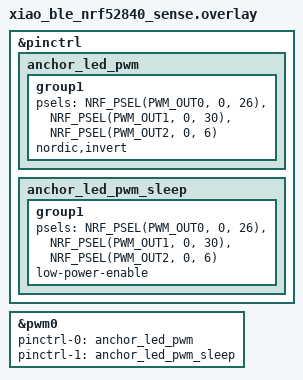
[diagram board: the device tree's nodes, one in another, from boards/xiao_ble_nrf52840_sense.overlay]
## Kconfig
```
mainmenu "ANCHOR native Nordic firmware"

source "Kconfig.zephyr"

config ANCHOR_LEGACY_BLE_DFU
	bool "Advertise legacy Bluetooth DFU for bench testing"
	help
	  Allow EdgeTX to enter the installed Adafruit S140 bootloader.
	  Enable only for controlled testing with the unsigned bench bootloader.
```

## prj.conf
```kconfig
#
# Copyright (c) 2025 Nordic Semiconductor
#
# SPDX-License-Identifier: LicenseRef-Nordic-5-Clause
#
CONFIG_NCS_SAMPLES_DEFAULTS=y

CONFIG_CONSOLE=y
CONFIG_CONSOLE_SUBSYS=y
CONFIG_CONSOLE_HANDLER=y
CONFIG_CONSOLE_GETCHAR=y

CONFIG_BT_DEVICE_NAME="Nordic_SCI"
CONFIG_BT=y
CONFIG_BT_SMP=y
CONFIG_BT_PERIPHERAL=y
CONFIG_BT_CENTRAL=y
CONFIG_BT_MAX_CONN=2
CONFIG_BT_BONDABLE=n

# Shorter Connection Intervals dependencies
CONFIG_BT_LE_EXTENDED_FEAT_SET=y
CONFIG_BT_SUBRATING=y

CONFIG_BT_FRAME_SPACE_UPDATE=y
CONFIG_BT_SHORTER_CONNECTION_INTERVALS=y

# Ensure the default event length is shorter than the minimum interval
CONFIG_BT_CTLR_SDC_MAX_CONN_EVENT_LEN_DEFAULT=750

CONFIG_BT_SCAN=y
CONFIG_BT_SCAN_FILTER_ENABLE=y
CONFIG_BT_SCAN_UUID_CNT=1

CONFIG_BT_LATENCY=y
CONFIG_BT_LATENCY_CLIENT=y

CONFIG_BT_GATT_CLIENT=y
CONFIG_BT_GATT_DM=y

CONFIG_BT_GAP_PERIPHERAL_PREF_PARAMS=n
CONFIG_BT_GAP_AUTO_UPDATE_CONN_PARAMS=n
CONFIG_BT_USER_PHY_UPDATE=y
CONFIG_BT_HCI_ERR_TO_STR=y

CONFIG_UART_INTERRUPT_DRIVEN=y
CONFIG_BUILD_OUTPUT_UF2=y

CONFIG_UART_ASYNC_API=y
CONFIG_UART_0_ASYNC=y
CONFIG_UART_USE_RUNTIME_CONFIGURE=y

CONFIG_UART_0_INTERRUPT_DRIVEN=n

CONFIG_UART_NRFX_UARTE_ENHANCED_RX=y

CONFIG_POWEROFF=y
CONFIG_PWM=y
```

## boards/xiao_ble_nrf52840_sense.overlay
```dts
#include <zephyr/dt-bindings/pinctrl/nrf-pinctrl.h>
&pinctrl {
    anchor_led_pwm: anchor_led_pwm {
        group1 {
            psels = <NRF_PSEL(PWM_OUT0, 0, 26)>,
                    <NRF_PSEL(PWM_OUT1, 0, 30)>,
                    <NRF_PSEL(PWM_OUT2, 0, 6)>;
            nordic,invert;
        };
    };
    anchor_led_pwm_sleep: anchor_led_pwm_sleep {
        group1 {
            psels = <NRF_PSEL(PWM_OUT0, 0, 26)>,
                    <NRF_PSEL(PWM_OUT1, 0, 30)>,
                    <NRF_PSEL(PWM_OUT2, 0, 6)>;
            low-power-enable;
        };
    };
};
&pwm0 {
    status = "okay";
    pinctrl-0 = <&anchor_led_pwm>;
    pinctrl-1 = <&anchor_led_pwm_sleep>;
    pinctrl-names = "default", "sleep";
};
```

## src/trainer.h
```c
#ifndef TRAINER_H
#define TRAINER_H
#include <stdint.h>
#include <stddef.h>
#include <stdbool.h>
/* One complete legacy or escaped PARA frame per notification. */
static inline bool trainer_decode(const uint8_t *p,size_t n,uint16_t out[8]){
 if(n<16||n>30||p[0]!=0x7e||p[n-1]!=0x7e)return false;
 uint8_t d[13],crc=0;size_t i=1;
 for(size_t j=0;j<13;j++){
  if(i>=n-1)return false;
  uint8_t b=p[i++];
  if(b==0x7d){if(i>=n-1)return false;b=p[i++]^0x20;if(b!=0x7d&&b!=0x7e)return false;}
  else if(b==0x7e)return false;
  d[j]=b;crc^=b;
 }
 if(d[0]!=0x80)return false;
 /* TinyGo emits checksum literally, including 7d or 7e. */
 if(i+1==n-1){if(p[i]!=crc)return false;}
 else if(i+2==n-1){if(p[i]!=0x7d||(p[i+1]^0x20)!=crc||(crc!=0x7d&&crc!=0x7e))return false;}
 else return false;
 for(size_t j=0;j<4;j++){
  const uint8_t *q=d+1+j*3;
  out[j*2]=q[0]|((uint16_t)(q[1]&0xf0)<<4);
  out[j*2+1]=((uint16_t)(q[1]&15)<<4)|(q[2]>>4)|((uint16_t)(q[2]&15)<<8);
 }
 return true;
}
#endif
```
